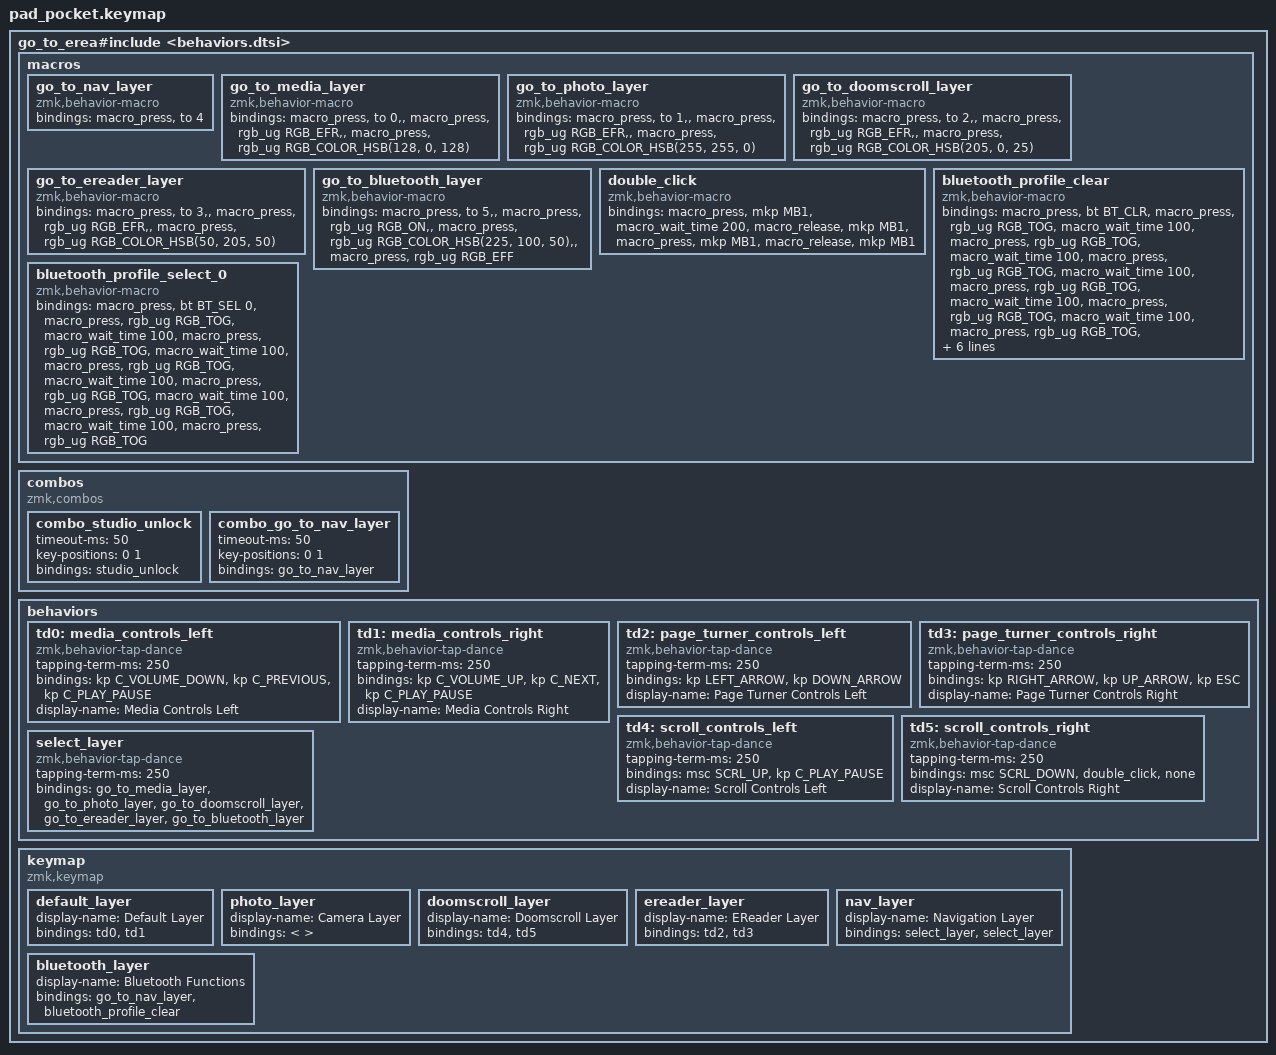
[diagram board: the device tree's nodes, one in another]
go_to_erea#include <behaviors.dtsi>
#include <dt-bindings/zmk/keys.h>
#include <dt-bindings/zmk/bt.h>
#include <dt-bindings/zmk/rgb.h>
#include <dt-bindings/zmk/pointing.h>

#define ZMK_POINTING_DEFAULT_SCRL_VAL 5

 {
     macros {
        go_to_nav_layer: go_to_nav_layer {
            compatible = "zmk,behavior-macro";
            #binding-cells = <0>;
            bindings = <&macro_press &to 4>; // Switch to nav layer (layer 5)
        };

        go_to_media_layer: go_to_media_layer {
            compatible = "zmk,behavior-macro";
            #binding-cells = <0>;
            bindings = <
                &macro_press &to 0,
                &macro_press &rgb_ug RGB_EFR,
                &macro_press &rgb_ug RGB_COLOR_HSB(128, 0, 128)
            >; 
        };

        go_to_photo_layer: go_to_photo_layer {
            compatible = "zmk,behavior-macro";
            #binding-cells = <0>;
            bindings = <
                &macro_press &to 1,
                &macro_press &rgb_ug RGB_EFR,
                &macro_press &rgb_ug RGB_COLOR_HSB(255, 255, 0)
            >; 
        };

        go_to_doomscroll_layer: go_to_doomscroll_layer {
            compatible = "zmk,behavior-macro";
            #binding-cells = <0>;
            bindings = <
                &macro_press &to 2,
                &macro_press &rgb_ug RGB_EFR,
                &macro_press &rgb_ug RGB_COLOR_HSB(205, 0, 25)
            >; 
        };

        go_to_ereader_layer: go_to_ereader_layer {
            compatible = "zmk,behavior-macro";
            #binding-cells = <0>;
            bindings = <
                &macro_press &to 3,
                &macro_press &rgb_ug RGB_EFR,
                &macro_press &rgb_ug RGB_COLOR_HSB(50, 205, 50)
            >; 
        };

        go_to_bluetooth_layer: go_to_bluetooth_layer {
            compatible = "zmk,behavior-macro";
            #binding-cells = <0>;
            bindings = <
                &macro_press &to 5,
                &macro_press &rgb_ug RGB_ON,
                &macro_press &rgb_ug RGB_COLOR_HSB(225, 100, 50),
                &macro_press &rgb_ug RGB_EFF
            >; 
        };

        double_click: double_click {
            compatible = "zmk,behavior-macro";
            #binding-cells = <0>;
            bindings = <&macro_press &mkp MB1>, <&macro_wait_time 200>, <&macro_release &mkp MB1>, <&macro_press &mkp MB1>, <&macro_release &mkp MB1>; 
        };

        bluetooth_profile_clear: bluetooth_profile_clear {
            compatible = "zmk,behavior-macro";
            #binding-cells = <0>;
            bindings = <&macro_press &bt BT_CLR>
            , <&macro_press &rgb_ug RGB_TOG>
            , <&macro_wait_time 100>
            , <&macro_press &rgb_ug RGB_TOG>
            ,  <&macro_wait_time 100>
            , <&macro_press &rgb_ug RGB_TOG>
            , <&macro_wait_time 100>
            , <&macro_press &rgb_ug RGB_TOG>
            , <&macro_wait_time 100>
            , <&macro_press &rgb_ug RGB_TOG>
            , <&macro_wait_time 100>
            , <&macro_press &rgb_ug RGB_TOG>
            , <&macro_wait_time 100>
            , <&macro_press &rgb_ug RGB_TOG>
            , <&macro_wait_time 100>
            , <&macro_press &rgb_ug RGB_TOG>
            , <&macro_wait_time 100>
            , <&macro_press &rgb_ug RGB_TOG>
            , <&macro_wait_time 100>
            , <&macro_press &rgb_ug RGB_TOG>; 
        };

        bluetooth_profile_select_0: bluetooth_profile_select_0 {
            compatible = "zmk,behavior-macro";
            #binding-cells = <0>;
            bindings = <&macro_press &bt BT_SEL 0>
            , <&macro_press &rgb_ug RGB_TOG>
            , <&macro_wait_time 100>
            , <&macro_press &rgb_ug RGB_TOG>
            , <&macro_wait_time 100>
            , <&macro_press &rgb_ug RGB_TOG>
            , <&macro_wait_time 100>
            , <&macro_press &rgb_ug RGB_TOG>
            , <&macro_wait_time 100>
            , <&macro_press &rgb_ug RGB_TOG>
            , <&macro_wait_time 100>
            , <&macro_press &rgb_ug RGB_TOG>; 
        };
    };

    combos {
        compatible = "zmk,combos";
        combo_studio_unlock {
            timeout-ms = <50>;
            key-positions = <0 1>;
            bindings = <&studio_unlock>;
        };

        combo_go_to_nav_layer {
            timeout-ms = <50>;
            key-positions = <0 1>; // Replace with actual key positions
            bindings = <&go_to_nav_layer>;
        };
    };

    behaviors {
        td0: media_controls_left {
            compatible = "zmk,behavior-tap-dance";
            #binding-cells = <0>;
            tapping-term-ms = <250>;
            bindings = <&kp C_VOLUME_DOWN>, <&kp C_PREVIOUS>, <&kp C_PLAY_PAUSE>;
            display-name = "Media Controls Left";
        };

        td1: media_controls_right {
            compatible = "zmk,behavior-tap-dance";
            #binding-cells = <0>;
            tapping-term-ms = <250>;
            bindings = <&kp C_VOLUME_UP>, <&kp C_NEXT>, <&kp C_PLAY_PAUSE>;
            display-name = "Media Controls Right";
        };

        td2: page_turner_controls_left {
            compatible = "zmk,behavior-tap-dance";
            #binding-cells = <0>;
            tapping-term-ms = <250>;
            bindings = <&kp LEFT_ARROW>, <&kp DOWN_ARROW>;
            display-name = "Page Turner Controls Left";
        };

        td3: page_turner_controls_right {
            compatible = "zmk,behavior-tap-dance";
            #binding-cells = <0>;
            tapping-term-ms = <250>;
            bindings = <&kp RIGHT_ARROW>, <&kp UP_ARROW>, <&kp ESC>;
            display-name = "Page Turner Controls Right";
        };

        td4: scroll_controls_left {
            compatible = "zmk,behavior-tap-dance";
            #binding-cells = <0>;
            tapping-term-ms = <250>;
            bindings = <&msc SCRL_UP>, <&kp C_PLAY_PAUSE>;
            display-name = "Scroll Controls Left";
        };

        td5: scroll_controls_right {
            compatible = "zmk,behavior-tap-dance";
            #binding-cells = <0>;
            tapping-term-ms = <250>;
            bindings = <&msc SCRL_DOWN>, <&double_click>, <&none>;
            display-name = "Scroll Controls Right";
        };

        select_layer: select_layer {
            compatible = "zmk,behavior-tap-dance";
            #binding-cells = <0>;
            tapping-term-ms = <250>;
            bindings = <
                &go_to_media_layer
                &go_to_photo_layer
                &go_to_doomscroll_layer
                &go_to_ereader_layer
                &go_to_bluetooth_layer
            >;
        }

        // td6: custom_right {
        //     compatible = "zmk,behavior-tap-dance";
        //     #binding-cells = <0>;
        //     tapping-term-ms = <250>;
        //     bindings = <&kp SPACE>, <&none>, <&go_to_bluetooth_layer>;
        //     display-name = "Spacebar Custom Left";
        // };
    };

    keymap {
        compatible = "zmk,keymap";

        default_layer { // Layer 0
            display-name = "Default Layer";
            // -------------------------------------
            //       |     Vol -    |     Vol +     |
            bindings = <
                &td0
                &td1
            >;
        };

        photo_layer {
            display-name = "Camera Layer";
            // -------------------------------------
            //       |     Vol -    |     Vol +     |
            bindings = <
                
            >;
        }

        doomscroll_layer {
            display-name= "Doomscroll Layer";
            bindings = <
                &td4
                &td5
            >;
        }

        ereader_layer {
            display-name= "EReader Layer";
            bindings = <
                &td2
                &td3
            >;
        }

        nav_layer {
            display-name= "Navigation Layer";
            bindings = <
                &select_layer
                &select_layer
            >;
        } 

        bluetooth_layer { // Layer 1
            display-name = "Bluetooth Functions";
            // -------------------------------------
            //       |     BT 0     |     BT 1     |
            bindings = <
                &go_to_nav_layer
                &bluetooth_profile_clear
            >;
        };
    };
 };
